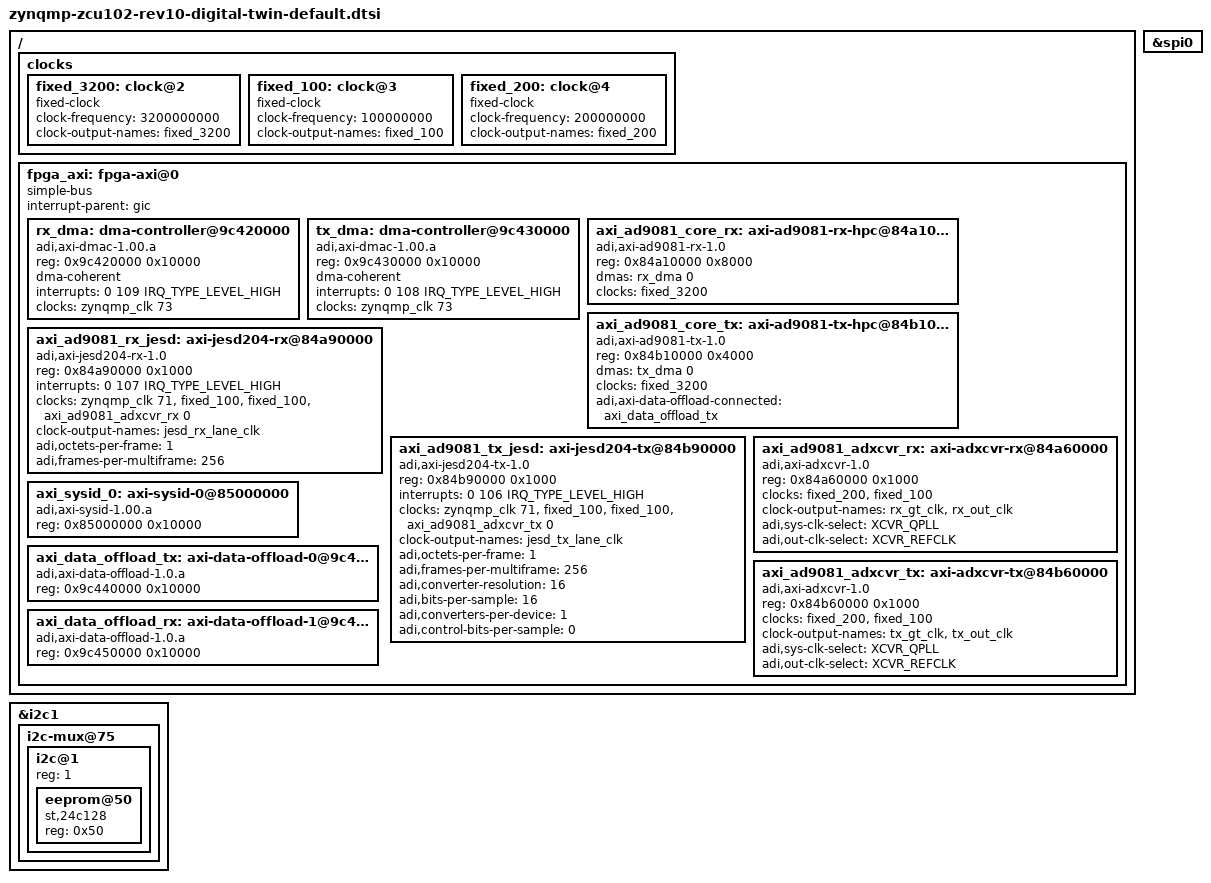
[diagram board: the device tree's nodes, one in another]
// SPDX-License-Identifier: GPL-2.0
/*
 * Analog Devices AD9081-FMC-EBZ
 * https://wiki.analog.com/resources/tools-software/linux-drivers/iio-mxfe/ad9081
 * https://wiki.analog.com/resources/eval/user-guides/ad9081_fmca_ebz/ad9081_fmca_ebz_hdl
 *
 * Copyright (C) 2019-2020 Analog Devices Inc.
 */

#include "zynqmp-zcu102-rev1.0.dts"
#include <dt-bindings/interrupt-controller/irq.h>
#include <dt-bindings/iio/adc/adi,ad9081.h>
#include <dt-bindings/jesd204/adxcvr.h>

// this is the dtsi for the zcu102 digital twin

&i2c1 {
	i2c-mux@75 {
		i2c@1 { /* HPC1 */
			#address-cells = <1>;
			#size-cells = <0>;
			reg = <1>;
			/* HPC1_IIC */
			eeprom@50 {
				compatible = "st,24c128", "atmel,24c128";
				reg = <0x50>;
			};
		};
	};
};

/ {
	clocks {
		fixed_3200: clock@2 {
			#clock-cells = <0>;
			compatible = "fixed-clock";
			clock-frequency = <3200000000>;
			clock-output-names = "fixed_3200";
		};

		fixed_100: clock@3 {
			#clock-cells = <0>;
			compatible = "fixed-clock";
			clock-frequency = <100000000>;
			clock-output-names = "fixed_100";
		};

		fixed_200: clock@4 {
			#clock-cells = <0>;
			compatible = "fixed-clock";
			clock-frequency = <200000000>;
			clock-output-names = "fixed_200";
		};
	};

	fpga_axi: fpga-axi@0 {
		interrupt-parent = <&gic>;
		compatible = "simple-bus";
		#address-cells = <0x1>;
		#size-cells = <0x1>;
		ranges = <0 0 0 0xffffffff>;

		rx_dma: dma-controller@9c420000 {
			compatible = "adi,axi-dmac-1.00.a";
			reg = <0x9c420000 0x10000>;
			#dma-cells = <1>;
			#clock-cells = <0>;
			dma-coherent;
			interrupts = <0 109 IRQ_TYPE_LEVEL_HIGH>;
			clocks = <&zynqmp_clk 73>;
		};

		tx_dma: dma-controller@9c430000 {
			compatible = "adi,axi-dmac-1.00.a";
			reg = <0x9c430000 0x10000>;
			#dma-cells = <1>;
			#clock-cells = <0>;
			dma-coherent;
			interrupts = <0 108 IRQ_TYPE_LEVEL_HIGH>;
			clocks = <&zynqmp_clk 73>;
		};

		axi_ad9081_core_rx: axi-ad9081-rx-hpc@84a10000 {
			compatible = "adi,axi-ad9081-rx-1.0";
			reg = <0x84a10000 0x8000>;
			dmas = <&rx_dma 0>;
			dma-names = "rx";
			clocks = <&fixed_3200>;
			clock-names = "sampl_clk";
		};

		axi_ad9081_core_tx: axi-ad9081-tx-hpc@84b10000 {
			compatible = "adi,axi-ad9081-tx-1.0";
			reg = <0x84b10000 0x4000>;
			dmas = <&tx_dma 0>;
			dma-names = "tx";
			clocks = <&fixed_3200>;
			clock-names = "sampl_clk";
			adi,axi-data-offload-connected = <&axi_data_offload_tx>;
		};

		axi_ad9081_rx_jesd: axi-jesd204-rx@84a90000 {
			compatible = "adi,axi-jesd204-rx-1.0";
			reg = <0x84a90000 0x1000>;

			interrupts = <0 107 IRQ_TYPE_LEVEL_HIGH>;

			clocks = <&zynqmp_clk 71>, <&fixed_100>, <&fixed_100>, <&axi_ad9081_adxcvr_rx 0>;
			clock-names = "s_axi_aclk", "device_clk", "link_clk", "lane_clk";

			#clock-cells = <0>;
			clock-output-names = "jesd_rx_lane_clk";

			adi,octets-per-frame = <1>;
			adi,frames-per-multiframe = <256>;
		};

		axi_ad9081_tx_jesd: axi-jesd204-tx@84b90000 {
			compatible = "adi,axi-jesd204-tx-1.0";
			reg = <0x84b90000 0x1000>;

			interrupts = <0 106 IRQ_TYPE_LEVEL_HIGH>;

			clocks = <&zynqmp_clk 71>, <&fixed_100>, <&fixed_100>, <&axi_ad9081_adxcvr_tx 0>;
			clock-names = "s_axi_aclk", "device_clk", "link_clk", "lane_clk";

			#clock-cells = <0>;
			clock-output-names = "jesd_tx_lane_clk";

			adi,octets-per-frame = <1>;
			adi,frames-per-multiframe = <256>;
			adi,converter-resolution = <16>;
			adi,bits-per-sample = <16>;
			adi,converters-per-device = <1>;
			adi,control-bits-per-sample = <0>;
		};

		axi_ad9081_adxcvr_rx: axi-adxcvr-rx@84a60000 {
			#address-cells = <1>;
			#size-cells = <0>;
			compatible = "adi,axi-adxcvr-1.0";
			reg = <0x84a60000 0x1000>;
			clocks = <&fixed_200>, <&fixed_100>;
			clock-names = "conv", "div40";

			#clock-cells = <1>;
			clock-output-names = "rx_gt_clk", "rx_out_clk";

			adi,sys-clk-select = <XCVR_QPLL>;
			adi,out-clk-select = <XCVR_REFCLK>;
		};

		axi_ad9081_adxcvr_tx: axi-adxcvr-tx@84b60000 {
			#address-cells = <1>;
			#size-cells = <0>;
			compatible = "adi,axi-adxcvr-1.0";
			reg = <0x84b60000 0x1000>;
			// 0 - means i'm using output (1 - means synthesizer), and 10 is out9
			clocks = <&fixed_200>, <&fixed_100>;
			clock-names = "conv", "div40";

			#clock-cells = <1>;
			clock-output-names = "tx_gt_clk", "tx_out_clk";

			adi,sys-clk-select = <XCVR_QPLL>;
			adi,out-clk-select = <XCVR_REFCLK>;
		};

		axi_sysid_0: axi-sysid-0@85000000 {
			compatible = "adi,axi-sysid-1.00.a";
			reg = <0x85000000 0x10000>;
		};

		axi_data_offload_tx: axi-data-offload-0@9c440000 {
			compatible = "adi,axi-data-offload-1.0.a";
			reg = <0x9c440000 0x10000>;
		};

		axi_data_offload_rx: axi-data-offload-1@9c450000 {
			compatible = "adi,axi-data-offload-1.0.a";
			reg = <0x9c450000 0x10000>;
		};
	};
};

&spi0 {
	status = "okay";
};

#define fmc_spi spi0
